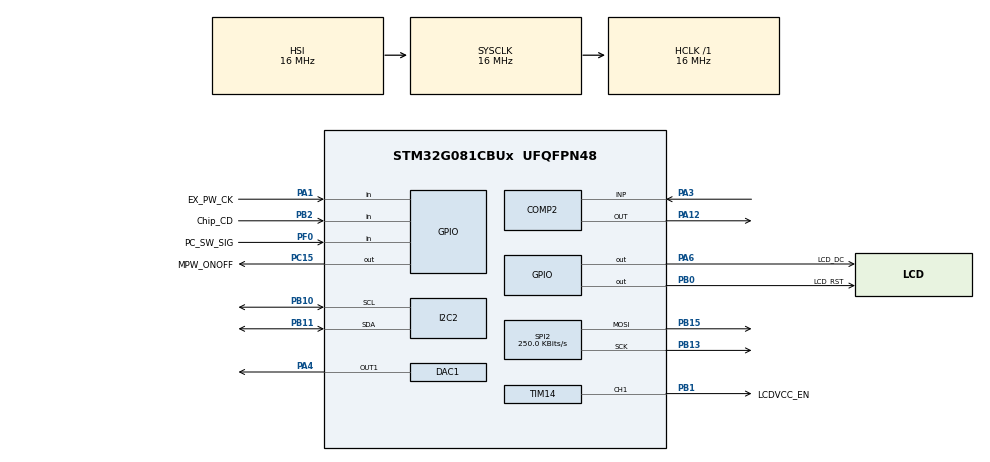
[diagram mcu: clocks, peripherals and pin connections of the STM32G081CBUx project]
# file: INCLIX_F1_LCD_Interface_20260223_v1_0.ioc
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COMP2.Hysteresis=COMP_HYSTERESIS_MEDIUM
COMP2.Mode=COMP_POWERMODE_MEDIUMSPEED
DAC1.DAC_Channel-DAC_OUT1_ExtAndInt=DAC_CHANNEL_1
I2C2.Timing=0x00503D58
Mcu.Family=STM32G0
Mcu.Name=STM32G081CBUx
Mcu.Package=UFQFPN48
PA1.GPIO_Label=EX_PW_CK
PA1.Signal=GPIO_Input
PA12\ [PA10].Mode=ExternalOutput
PA12\ [PA10].Signal=COMP2_OUT
PA13.Mode=Serial_Wire
PA13.Signal=SYS_SWDIO
PA14-BOOT0.Mode=Serial_Wire
PA14-BOOT0.Signal=SYS_SWCLK
PA3.Mode=INP
PA3.Signal=COMP2_INP
PA4.Signal=COMP_DAC11_group
PA6.GPIO_Label=LCD_DC
PA6.Signal=GPIO_Output
PB0.GPIO_Label=LCD_RST
PB0.PinState=GPIO_PIN_SET
PB0.Signal=GPIO_Output
PB1.GPIO_Label=LCDVCC_EN
PB1.GPIO_ModeDefaultPP=GPIO_MODE_AF_PP
PB1.Signal=S_TIM14_CH1
PB10.Mode=I2C
PB10.Signal=I2C2_SCL
PB11.Mode=I2C
PB11.Signal=I2C2_SDA
PB13.Mode=TX_Only_Simplex_Unidirect_Master
PB13.Signal=SPI2_SCK
PB15.Mode=TX_Only_Simplex_Unidirect_Master
PB15.Signal=SPI2_MOSI
PB2.GPIO_Label=Chip_CD
PB2.Signal=GPIO_Input
PC15-OSC32_OUT\ (PC15).GPIO_Label=MPW_ONOFF
PC15-OSC32_OUT\ (PC15).PinState=GPIO_PIN_SET
PC15-OSC32_OUT\ (PC15).Signal=GPIO_Output
PF0-OSC_IN\ (PF0).GPIO_Label=PC_SW_SIG
PF0-OSC_IN\ (PF0).Signal=GPIO_Input
ProjectManager.HeapSize=0x200
ProjectManager.StackSize=0x400
ProjectManager.TargetToolchain=EWARM V8.50
RCC.AHBFreq_Value=16000000
RCC.CortexFreq_Value=16000000
RCC.EXTERNAL_CLOCK_VALUE=48000
RCC.HCLKFreq_Value=16000000
RCC.HSE_VALUE=8000000
RCC.HSI_VALUE=16000000
RCC.LSE_VALUE=32768
RCC.SYSCLKFreq_VALUE=16000000
RCC.VCOOutputFreq_Value=128000000
SH.COMP_DAC11_group.0=DAC1_OUT1,DAC_OUT1_ExtAndInt
SH.S_TIM14_CH1.0=TIM14_CH1,PWM Generation1 CH1
SPI2.BaudRatePrescaler=SPI_BAUDRATEPRESCALER_64
SPI2.CalculateBaudRate=250.0 KBits/s
SPI2.DataSize=SPI_DATASIZE_8BIT
SPI2.Direction=SPI_DIRECTION_2LINES
SPI2.Mode=SPI_MODE_MASTER
SPI2.VirtualType=VM_MASTER
TIM14.AutoReloadPreload=TIM_AUTORELOAD_PRELOAD_ENABLE
TIM14.Channel=TIM_CHANNEL_1
TIM14.Period=999
TIM14.Prescaler=15
VP_COMP2_VS_DACOUT1.Mode=INM_DACOUT1
VP_TIM14_VS_ClockSourceINT.Mode=Enable_Timer
board=custom

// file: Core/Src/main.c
/* USER CODE BEGIN Header */
/**
  ******************************************************************************
  * @file           : main.c
  * @brief          : Main program body
  ******************************************************************************
  * @attention
  *
  * Copyright (c) 2026 STMicroelectronics.
  * All rights reserved.
  *
  * This software is licensed under terms that can be found in the LICENSE file
  * in the root directory of this software component.
  * If no LICENSE file comes with this software, it is provided AS-IS.
  *
  ******************************************************************************
  */
/* USER CODE END Header */
#include "main.h"

/* USER CODE BEGIN Includes */
#include "User_Main.h"

/* USER CODE END Includes */

COMP_HandleTypeDef hcomp2;

DAC_HandleTypeDef hdac1;

I2C_HandleTypeDef hi2c2;

SPI_HandleTypeDef hspi2;

TIM_HandleTypeDef htim14;

void SystemClock_Config(void);
static void MX_GPIO_Init(void);
static void MX_SPI2_Init(void);
static void MX_COMP2_Init(void);
static void MX_DAC1_Init(void);
static void MX_TIM14_Init(void);
static void MX_I2C2_Init(void);

int main(void)
{

  /* MCU Configuration--------------------------------------------------------*/

  /* Reset of all peripherals, Initializes the Flash interface and the Systick. */
  HAL_Init();

  /* Configure the system clock */
  SystemClock_Config();

  /* Initialize all configured peripherals */
  MX_GPIO_Init();
  MX_SPI2_Init();
  MX_COMP2_Init();
  MX_DAC1_Init();
  MX_TIM14_Init();
  MX_I2C2_Init();
  /* USER CODE BEGIN 2 */
  User_Main_Init();

  /* USER CODE END 2 */

  /* Infinite loop */
  while (1)
  {

    /* USER CODE BEGIN 3 */
    User_Main_Run();
  }
  /* USER CODE END 3 */
}

void SystemClock_Config(void)
{
  RCC_OscInitTypeDef RCC_OscInitStruct = {0};
  RCC_ClkInitTypeDef RCC_ClkInitStruct = {0};

  /** Configure the main internal regulator output voltage
  */
  HAL_PWREx_ControlVoltageScaling(PWR_REGULATOR_VOLTAGE_SCALE1);

  /** Initializes the RCC Oscillators according to the specified parameters
  * in the RCC_OscInitTypeDef structure.
  */
  RCC_OscInitStruct.OscillatorType = RCC_OSCILLATORTYPE_HSI;
  RCC_OscInitStruct.HSIState = RCC_HSI_ON;
  RCC_OscInitStruct.HSIDiv = RCC_HSI_DIV1;
  RCC_OscInitStruct.HSICalibrationValue = RCC_HSICALIBRATION_DEFAULT;
  RCC_OscInitStruct.PLL.PLLState = RCC_PLL_NONE;
  if (HAL_RCC_OscConfig(&RCC_OscInitStruct) != HAL_OK)
  {
    Error_Handler();
  }

  /** Initializes the CPU, AHB and APB buses clocks
  */
  RCC_ClkInitStruct.ClockType = RCC_CLOCKTYPE_HCLK|RCC_CLOCKTYPE_SYSCLK
                              |RCC_CLOCKTYPE_PCLK1;
  RCC_ClkInitStruct.SYSCLKSource = RCC_SYSCLKSOURCE_HSI;
  RCC_ClkInitStruct.AHBCLKDivider = RCC_SYSCLK_DIV1;
  RCC_ClkInitStruct.APB1CLKDivider = RCC_HCLK_DIV1;

  if (HAL_RCC_ClockConfig(&RCC_ClkInitStruct, FLASH_LATENCY_0) != HAL_OK)
  {
    Error_Handler();
  }
}

static void MX_COMP2_Init(void)
{

  hcomp2.Instance = COMP2;
  hcomp2.Init.InputPlus = COMP_INPUT_PLUS_IO3;
  hcomp2.Init.InputMinus = COMP_INPUT_MINUS_DAC1_CH1;
  hcomp2.Init.OutputPol = COMP_OUTPUTPOL_NONINVERTED;
  hcomp2.Init.WindowOutput = COMP_WINDOWOUTPUT_EACH_COMP;
  hcomp2.Init.Hysteresis = COMP_HYSTERESIS_MEDIUM;
  hcomp2.Init.BlankingSrce = COMP_BLANKINGSRC_NONE;
  hcomp2.Init.Mode = COMP_POWERMODE_MEDIUMSPEED;
  hcomp2.Init.WindowMode = COMP_WINDOWMODE_DISABLE;
  hcomp2.Init.TriggerMode = COMP_TRIGGERMODE_NONE;
  if (HAL_COMP_Init(&hcomp2) != HAL_OK)
  {
    Error_Handler();
  }

}

static void MX_DAC1_Init(void)
{

  DAC_ChannelConfTypeDef sConfig = {0};

  /** DAC Initialization
  */
  hdac1.Instance = DAC1;
  if (HAL_DAC_Init(&hdac1) != HAL_OK)
  {
    Error_Handler();
  }

  /** DAC channel OUT1 config
  */
  sConfig.DAC_SampleAndHold = DAC_SAMPLEANDHOLD_DISABLE;
  sConfig.DAC_Trigger = DAC_TRIGGER_NONE;
  sConfig.DAC_OutputBuffer = DAC_OUTPUTBUFFER_ENABLE;
  sConfig.DAC_ConnectOnChipPeripheral = DAC_CHIPCONNECT_ENABLE;
  sConfig.DAC_UserTrimming = DAC_TRIMMING_FACTORY;
  if (HAL_DAC_ConfigChannel(&hdac1, &sConfig, DAC_CHANNEL_1) != HAL_OK)
  {
    Error_Handler();
  }

}

static void MX_I2C2_Init(void)
{

  hi2c2.Instance = I2C2;
  hi2c2.Init.Timing = 0x00503D58;
  hi2c2.Init.OwnAddress1 = 0;
  hi2c2.Init.AddressingMode = I2C_ADDRESSINGMODE_7BIT;
  hi2c2.Init.DualAddressMode = I2C_DUALADDRESS_DISABLE;
  hi2c2.Init.OwnAddress2 = 0;
  hi2c2.Init.OwnAddress2Masks = I2C_OA2_NOMASK;
  hi2c2.Init.GeneralCallMode = I2C_GENERALCALL_DISABLE;
  hi2c2.Init.NoStretchMode = I2C_NOSTRETCH_DISABLE;
  if (HAL_I2C_Init(&hi2c2) != HAL_OK)
  {
    Error_Handler();
  }

  /** Configure Analogue filter
  */
  if (HAL_I2CEx_ConfigAnalogFilter(&hi2c2, I2C_ANALOGFILTER_ENABLE) != HAL_OK)
  {
    Error_Handler();
  }

  /** Configure Digital filter
  */
  if (HAL_I2CEx_ConfigDigitalFilter(&hi2c2, 0) != HAL_OK)
  {
    Error_Handler();
  }

}

static void MX_SPI2_Init(void)
{

  /* SPI2 parameter configuration*/
  hspi2.Instance = SPI2;
  hspi2.Init.Mode = SPI_MODE_MASTER;
  hspi2.Init.Direction = SPI_DIRECTION_2LINES;
  hspi2.Init.DataSize = SPI_DATASIZE_8BIT;
  hspi2.Init.CLKPolarity = SPI_POLARITY_LOW;
  hspi2.Init.CLKPhase = SPI_PHASE_1EDGE;
  hspi2.Init.NSS = SPI_NSS_SOFT;
  hspi2.Init.BaudRatePrescaler = SPI_BAUDRATEPRESCALER_64;
  hspi2.Init.FirstBit = SPI_FIRSTBIT_MSB;
  hspi2.Init.TIMode = SPI_TIMODE_DISABLE;
  hspi2.Init.CRCCalculation = SPI_CRCCALCULATION_DISABLE;
  hspi2.Init.CRCPolynomial = 7;
  hspi2.Init.CRCLength = SPI_CRC_LENGTH_DATASIZE;
  hspi2.Init.NSSPMode = SPI_NSS_PULSE_ENABLE;
  if (HAL_SPI_Init(&hspi2) != HAL_OK)
  {
    Error_Handler();
  }

}

static void MX_TIM14_Init(void)
{

  TIM_OC_InitTypeDef sConfigOC = {0};

  htim14.Instance = TIM14;
  htim14.Init.Prescaler = 15;
  htim14.Init.CounterMode = TIM_COUNTERMODE_UP;
  htim14.Init.Period = 999;
  htim14.Init.ClockDivision = TIM_CLOCKDIVISION_DIV1;
  htim14.Init.AutoReloadPreload = TIM_AUTORELOAD_PRELOAD_ENABLE;
  if (HAL_TIM_Base_Init(&htim14) != HAL_OK)
  {
    Error_Handler();
  }
  if (HAL_TIM_PWM_Init(&htim14) != HAL_OK)
  {
    Error_Handler();
  }
  sConfigOC.OCMode = TIM_OCMODE_PWM1;
  sConfigOC.Pulse = 0;
  sConfigOC.OCPolarity = TIM_OCPOLARITY_HIGH;
  sConfigOC.OCFastMode = TIM_OCFAST_DISABLE;
  if (HAL_TIM_PWM_ConfigChannel(&htim14, &sConfigOC, TIM_CHANNEL_1) != HAL_OK)
  {
    Error_Handler();
  }
  HAL_TIM_MspPostInit(&htim14);

}

static void MX_GPIO_Init(void)
{
  GPIO_InitTypeDef GPIO_InitStruct = {0};

  /* GPIO Ports Clock Enable */
  __HAL_RCC_GPIOC_CLK_ENABLE();
  __HAL_RCC_GPIOF_CLK_ENABLE();
  __HAL_RCC_GPIOA_CLK_ENABLE();
  __HAL_RCC_GPIOB_CLK_ENABLE();

  /*Configure GPIO pin Output Level */
  HAL_GPIO_WritePin(MPW_ONOFF_GPIO_Port, MPW_ONOFF_Pin, GPIO_PIN_SET);

  /*Configure GPIO pin Output Level */
  HAL_GPIO_WritePin(LCD_DC_GPIO_Port, LCD_DC_Pin, GPIO_PIN_RESET);

  /*Configure GPIO pin Output Level */
  HAL_GPIO_WritePin(LCD_RST_GPIO_Port, LCD_RST_Pin, GPIO_PIN_SET);

  /*Configure GPIO pin : MPW_ONOFF_Pin */
  GPIO_InitStruct.Pin = MPW_ONOFF_Pin;
  GPIO_InitStruct.Mode = GPIO_MODE_OUTPUT_PP;
  GPIO_InitStruct.Pull = GPIO_NOPULL;
  GPIO_InitStruct.Speed = GPIO_SPEED_FREQ_LOW;
  HAL_GPIO_Init(MPW_ONOFF_GPIO_Port, &GPIO_InitStruct);

  /*Configure GPIO pin : PC_SW_SIG_Pin */
  GPIO_InitStruct.Pin = PC_SW_SIG_Pin;
  GPIO_InitStruct.Mode = GPIO_MODE_INPUT;
  GPIO_InitStruct.Pull = GPIO_NOPULL;
  HAL_GPIO_Init(PC_SW_SIG_GPIO_Port, &GPIO_InitStruct);

  /*Configure GPIO pin : EX_PW_CK_Pin */
  GPIO_InitStruct.Pin = EX_PW_CK_Pin;
  GPIO_InitStruct.Mode = GPIO_MODE_INPUT;
  GPIO_InitStruct.Pull = GPIO_NOPULL;
  HAL_GPIO_Init(EX_PW_CK_GPIO_Port, &GPIO_InitStruct);

  /*Configure GPIO pin : LCD_DC_Pin */
  GPIO_InitStruct.Pin = LCD_DC_Pin;
  GPIO_InitStruct.Mode = GPIO_MODE_OUTPUT_PP;
  GPIO_InitStruct.Pull = GPIO_NOPULL;
  GPIO_InitStruct.Speed = GPIO_SPEED_FREQ_LOW;
  HAL_GPIO_Init(LCD_DC_GPIO_Port, &GPIO_InitStruct);

  /*Configure GPIO pin : LCD_RST_Pin */
  GPIO_InitStruct.Pin = LCD_RST_Pin;
  GPIO_InitStruct.Mode = GPIO_MODE_OUTPUT_PP;
  GPIO_InitStruct.Pull = GPIO_NOPULL;
  GPIO_InitStruct.Speed = GPIO_SPEED_FREQ_LOW;
  HAL_GPIO_Init(LCD_RST_GPIO_Port, &GPIO_InitStruct);

  /*Configure GPIO pin : Chip_CD_Pin */
  GPIO_InitStruct.Pin = Chip_CD_Pin;
  GPIO_InitStruct.Mode = GPIO_MODE_INPUT;
  GPIO_InitStruct.Pull = GPIO_NOPULL;
  HAL_GPIO_Init(Chip_CD_GPIO_Port, &GPIO_InitStruct);

}

void Error_Handler(void)
{
  __disable_irq();
  while (1)
  {
  }
}
